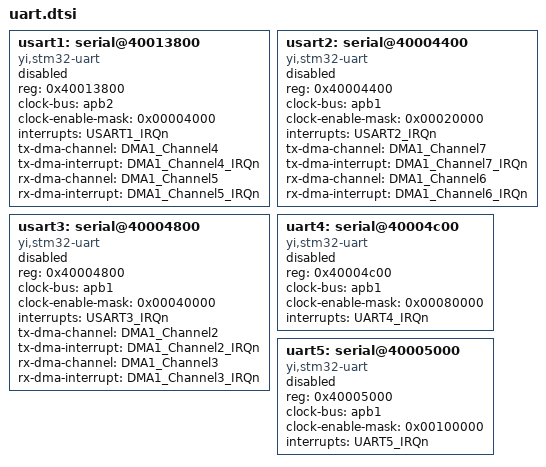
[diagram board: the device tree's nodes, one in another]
    usart1: serial@40013800 { compatible = "yi,stm32-uart"; reg = <0x40013800>; clock-bus = "apb2"; clock-enable-mask = <0x00004000>; interrupts = "USART1_IRQn"; tx-dma-channel = "DMA1_Channel4"; tx-dma-interrupt = "DMA1_Channel4_IRQn"; rx-dma-channel = "DMA1_Channel5"; rx-dma-interrupt = "DMA1_Channel5_IRQn"; status = "disabled"; };
    usart2: serial@40004400 { compatible = "yi,stm32-uart"; reg = <0x40004400>; clock-bus = "apb1"; clock-enable-mask = <0x00020000>; interrupts = "USART2_IRQn"; tx-dma-channel = "DMA1_Channel7"; tx-dma-interrupt = "DMA1_Channel7_IRQn"; rx-dma-channel = "DMA1_Channel6"; rx-dma-interrupt = "DMA1_Channel6_IRQn"; status = "disabled"; };
    usart3: serial@40004800 { compatible = "yi,stm32-uart"; reg = <0x40004800>; clock-bus = "apb1"; clock-enable-mask = <0x00040000>; interrupts = "USART3_IRQn"; tx-dma-channel = "DMA1_Channel2"; tx-dma-interrupt = "DMA1_Channel2_IRQn"; rx-dma-channel = "DMA1_Channel3"; rx-dma-interrupt = "DMA1_Channel3_IRQn"; status = "disabled"; };
    uart4: serial@40004c00 { compatible = "yi,stm32-uart"; reg = <0x40004c00>; clock-bus = "apb1"; clock-enable-mask = <0x00080000>; interrupts = "UART4_IRQn"; status = "disabled"; };
    uart5: serial@40005000 { compatible = "yi,stm32-uart"; reg = <0x40005000>; clock-bus = "apb1"; clock-enable-mask = <0x00100000>; interrupts = "UART5_IRQn"; status = "disabled"; };
